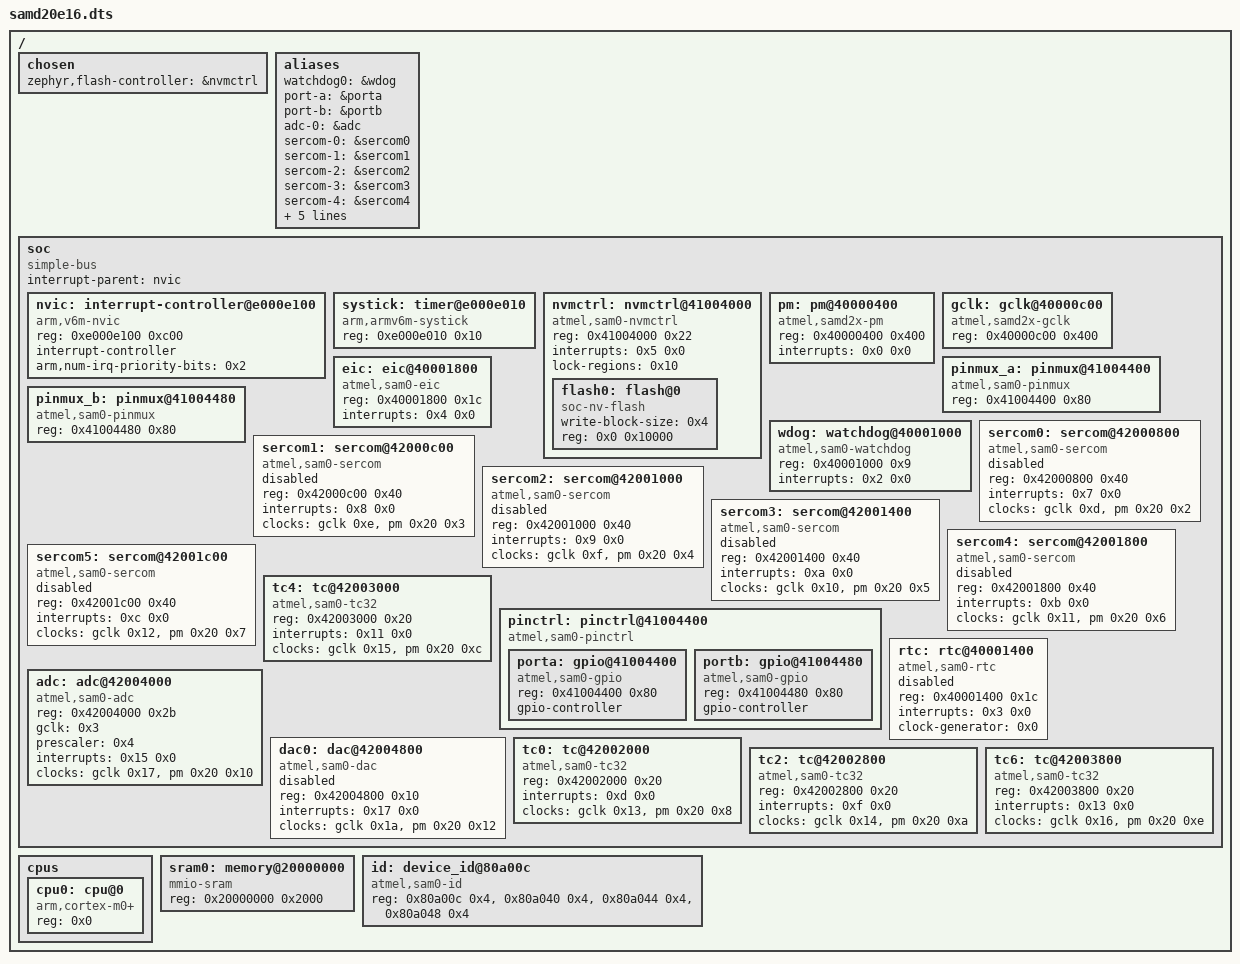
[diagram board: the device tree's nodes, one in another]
/dts-v1/;

/ {
	#address-cells = < 0x1 >;
	#size-cells = < 0x1 >;
	chosen {
		zephyr,flash-controller = &nvmctrl;
	};
	aliases {
		watchdog0 = &wdog;
		port-a = &porta;
		port-b = &portb;
		adc-0 = &adc;
		sercom-0 = &sercom0;
		sercom-1 = &sercom1;
		sercom-2 = &sercom2;
		sercom-3 = &sercom3;
		sercom-4 = &sercom4;
		sercom-5 = &sercom5;
		tc-4 = &tc4;
		tc-0 = &tc0;
		tc-2 = &tc2;
		tc-6 = &tc6;
	};
	soc {
		#address-cells = < 0x1 >;
		#size-cells = < 0x1 >;
		compatible = "simple-bus";
		interrupt-parent = < &nvic >;
		ranges;
		nvic: interrupt-controller@e000e100 {
			#address-cells = < 0x1 >;
			compatible = "arm,v6m-nvic";
			reg = < 0xe000e100 0xc00 >;
			interrupt-controller;
			#interrupt-cells = < 0x2 >;
			arm,num-irq-priority-bits = < 0x2 >;
			phandle = < 0x1 >;
		};
		systick: timer@e000e010 {
			compatible = "arm,armv6m-systick";
			reg = < 0xe000e010 0x10 >;
		};
		nvmctrl: nvmctrl@41004000 {
			compatible = "atmel,sam0-nvmctrl";
			reg = < 0x41004000 0x22 >;
			interrupts = < 0x5 0x0 >;
			lock-regions = < 0x10 >;
			#address-cells = < 0x1 >;
			#size-cells = < 0x1 >;
			flash0: flash@0 {
				compatible = "soc-nv-flash";
				write-block-size = < 0x4 >;
				reg = < 0x0 0x10000 >;
			};
		};
		pm: pm@40000400 {
			compatible = "atmel,samd2x-pm";
			reg = < 0x40000400 0x400 >;
			interrupts = < 0x0 0x0 >;
			#clock-cells = < 0x2 >;
			phandle = < 0x3 >;
		};
		gclk: gclk@40000c00 {
			compatible = "atmel,samd2x-gclk";
			reg = < 0x40000c00 0x400 >;
			#clock-cells = < 0x1 >;
			phandle = < 0x2 >;
		};
		eic: eic@40001800 {
			compatible = "atmel,sam0-eic";
			reg = < 0x40001800 0x1c >;
			interrupts = < 0x4 0x0 >;
		};
		pinmux_a: pinmux@41004400 {
			compatible = "atmel,sam0-pinmux";
			reg = < 0x41004400 0x80 >;
		};
		pinmux_b: pinmux@41004480 {
			compatible = "atmel,sam0-pinmux";
			reg = < 0x41004480 0x80 >;
		};
		wdog: watchdog@40001000 {
			compatible = "atmel,sam0-watchdog";
			reg = < 0x40001000 0x9 >;
			interrupts = < 0x2 0x0 >;
		};
		sercom0: sercom@42000800 {
			compatible = "atmel,sam0-sercom";
			reg = < 0x42000800 0x40 >;
			status = "disabled";
			interrupts = < 0x7 0x0 >;
			clocks = < &gclk 0xd >, < &pm 0x20 0x2 >;
			clock-names = "GCLK", "PM";
		};
		sercom1: sercom@42000c00 {
			compatible = "atmel,sam0-sercom";
			reg = < 0x42000c00 0x40 >;
			status = "disabled";
			interrupts = < 0x8 0x0 >;
			clocks = < &gclk 0xe >, < &pm 0x20 0x3 >;
			clock-names = "GCLK", "PM";
		};
		sercom2: sercom@42001000 {
			compatible = "atmel,sam0-sercom";
			reg = < 0x42001000 0x40 >;
			status = "disabled";
			interrupts = < 0x9 0x0 >;
			clocks = < &gclk 0xf >, < &pm 0x20 0x4 >;
			clock-names = "GCLK", "PM";
		};
		sercom3: sercom@42001400 {
			compatible = "atmel,sam0-sercom";
			reg = < 0x42001400 0x40 >;
			status = "disabled";
			interrupts = < 0xa 0x0 >;
			clocks = < &gclk 0x10 >, < &pm 0x20 0x5 >;
			clock-names = "GCLK", "PM";
		};
		sercom4: sercom@42001800 {
			compatible = "atmel,sam0-sercom";
			reg = < 0x42001800 0x40 >;
			status = "disabled";
			interrupts = < 0xb 0x0 >;
			clocks = < &gclk 0x11 >, < &pm 0x20 0x6 >;
			clock-names = "GCLK", "PM";
		};
		sercom5: sercom@42001c00 {
			compatible = "atmel,sam0-sercom";
			reg = < 0x42001c00 0x40 >;
			status = "disabled";
			interrupts = < 0xc 0x0 >;
			clocks = < &gclk 0x12 >, < &pm 0x20 0x7 >;
			clock-names = "GCLK", "PM";
		};
		tc4: tc@42003000 {
			compatible = "atmel,sam0-tc32";
			reg = < 0x42003000 0x20 >;
			interrupts = < 0x11 0x0 >;
			clocks = < &gclk 0x15 >, < &pm 0x20 0xc >;
			clock-names = "GCLK", "PM";
		};
		pinctrl: pinctrl@41004400 {
			compatible = "atmel,sam0-pinctrl";
			#address-cells = < 0x1 >;
			#size-cells = < 0x1 >;
			ranges = < 0x41004400 0x41004400 0x100 >;
			porta: gpio@41004400 {
				compatible = "atmel,sam0-gpio";
				reg = < 0x41004400 0x80 >;
				gpio-controller;
				#gpio-cells = < 0x2 >;
				#atmel,pin-cells = < 0x2 >;
			};
			portb: gpio@41004480 {
				compatible = "atmel,sam0-gpio";
				reg = < 0x41004480 0x80 >;
				gpio-controller;
				#gpio-cells = < 0x2 >;
				#atmel,pin-cells = < 0x2 >;
			};
		};
		rtc: rtc@40001400 {
			compatible = "atmel,sam0-rtc";
			reg = < 0x40001400 0x1c >;
			interrupts = < 0x3 0x0 >;
			clock-generator = < 0x0 >;
			status = "disabled";
		};
		adc: adc@42004000 {
			compatible = "atmel,sam0-adc";
			reg = < 0x42004000 0x2b >;
			gclk = < 0x3 >;
			prescaler = < 0x4 >;
			#io-channel-cells = < 0x1 >;
			interrupts = < 0x15 0x0 >;
			interrupt-names = "resrdy";
			clocks = < &gclk 0x17 >, < &pm 0x20 0x10 >;
			clock-names = "GCLK", "PM";
		};
		dac0: dac@42004800 {
			compatible = "atmel,sam0-dac";
			status = "disabled";
			reg = < 0x42004800 0x10 >;
			#io-channel-cells = < 0x0 >;
			interrupts = < 0x17 0x0 >;
			clocks = < &gclk 0x1a >, < &pm 0x20 0x12 >;
			clock-names = "GCLK", "PM";
		};
		tc0: tc@42002000 {
			compatible = "atmel,sam0-tc32";
			reg = < 0x42002000 0x20 >;
			interrupts = < 0xd 0x0 >;
			clocks = < &gclk 0x13 >, < &pm 0x20 0x8 >;
			clock-names = "GCLK", "PM";
		};
		tc2: tc@42002800 {
			compatible = "atmel,sam0-tc32";
			reg = < 0x42002800 0x20 >;
			interrupts = < 0xf 0x0 >;
			clocks = < &gclk 0x14 >, < &pm 0x20 0xa >;
			clock-names = "GCLK", "PM";
		};
		tc6: tc@42003800 {
			compatible = "atmel,sam0-tc32";
			reg = < 0x42003800 0x20 >;
			interrupts = < 0x13 0x0 >;
			clocks = < &gclk 0x16 >, < &pm 0x20 0xe >;
			clock-names = "GCLK", "PM";
		};
	};
	cpus {
		#address-cells = < 0x1 >;
		#size-cells = < 0x0 >;
		cpu0: cpu@0 {
			device_type = "cpu";
			compatible = "arm,cortex-m0+";
			reg = < 0x0 >;
		};
	};
	sram0: memory@20000000 {
		compatible = "mmio-sram";
		reg = < 0x20000000 0x2000 >;
	};
	id: device_id@80a00c {
		compatible = "atmel,sam0-id";
		reg = < 0x80a00c 0x4 >, < 0x80a040 0x4 >, < 0x80a044 0x4 >, < 0x80a048 0x4 >;
	};
};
